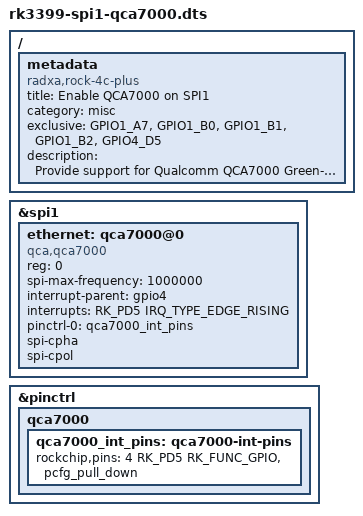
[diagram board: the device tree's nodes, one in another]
/dts-v1/;
/plugin/;

#include <dt-bindings/gpio/gpio.h>
#include <dt-bindings/pinctrl/rockchip.h>
#include <dt-bindings/interrupt-controller/irq.h>

/ {
	metadata {
		title = "Enable QCA7000 on SPI1";
		compatible = "radxa,rock-4c-plus";
		category = "misc";
		exclusive = "GPIO1_A7", "GPIO1_B0", "GPIO1_B1", "GPIO1_B2", "GPIO4_D5";
		description = "Provide support for Qualcomm QCA7000 Green-PHY on GPIO pins.\nPin definition:\nMOSI=19 MISO=21 SCK=23 CS=24 INT=22";
	};

	fragment@0 {
		target = <&spi1>;
		__overlay__ {
			#address-cells = <1>;
			#size-cells = <0>;
			status = "okay";

			ethernet: qca7000@0 {
				compatible = "qca,qca7000";
				reg = <0>;
				spi-max-frequency = <1000000>;
				interrupt-parent = <&gpio4>;
				interrupts = <RK_PD5 IRQ_TYPE_EDGE_RISING>;
				pinctrl-names = "default";
				pinctrl-0 = <&qca7000_int_pins>;
				spi-cpha;
				spi-cpol;
			};
		};
	};

	fragment@1 {
		target = <&pinctrl>;
		__overlay__ {
			qca7000 {
				qca7000_int_pins: qca7000-int-pins {
					rockchip,pins = <4 RK_PD5 RK_FUNC_GPIO &pcfg_pull_down>;
				};
			};
		};
	};
};
